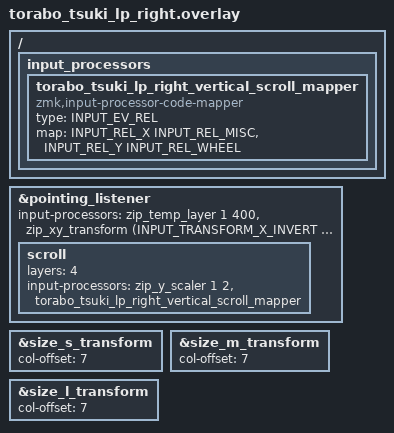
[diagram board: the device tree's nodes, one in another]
#include "torabo_tsuki_lp.dtsi"
#include <input/processors.dtsi>
#include <dt-bindings/zmk/input_transform.h>
#include <zephyr/dt-bindings/input/input-event-codes.h>

/ {
    input_processors {
        torabo_tsuki_lp_right_vertical_scroll_mapper: torabo_tsuki_lp_right_vertical_scroll_mapper {
            compatible = "zmk,input-processor-code-mapper";
            #input-processor-cells = <0>;
            type = <INPUT_EV_REL>;
            map = <INPUT_REL_X INPUT_REL_MISC>,
                  <INPUT_REL_Y INPUT_REL_WHEEL>;
        };
    };
};

&pointing_listener {
    input-processors = <&zip_temp_layer 1 400>,
                       <&zip_xy_transform (INPUT_TRANSFORM_X_INVERT | INPUT_TRANSFORM_Y_INVERT)>;

    scroll {
        layers = <4>;
        input-processors = <&zip_y_scaler 1 2>,
                           <&torabo_tsuki_lp_right_vertical_scroll_mapper>;
    };
};

&size_s_transform {
    col-offset = <7>;
};

&size_m_transform {
    col-offset = <7>;
};

&size_l_transform {
    col-offset = <7>;
};
